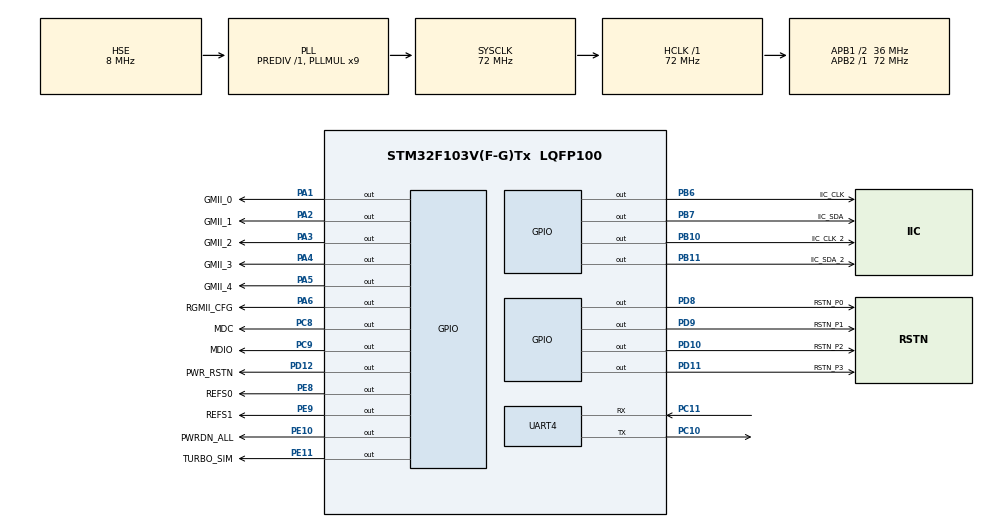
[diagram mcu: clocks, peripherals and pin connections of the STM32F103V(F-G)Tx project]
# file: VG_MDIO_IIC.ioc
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Dma.Request0=UART4_RX
Dma.UART4_RX.0.Direction=DMA_PERIPH_TO_MEMORY
Dma.UART4_RX.0.Instance=DMA2_Channel3
Dma.UART4_RX.0.MemDataAlignment=DMA_MDATAALIGN_BYTE
Dma.UART4_RX.0.MemInc=DMA_MINC_ENABLE
Dma.UART4_RX.0.Mode=DMA_NORMAL
Dma.UART4_RX.0.PeriphDataAlignment=DMA_PDATAALIGN_BYTE
Dma.UART4_RX.0.PeriphInc=DMA_PINC_DISABLE
Dma.UART4_RX.0.Priority=DMA_PRIORITY_LOW
Mcu.Family=STM32F1
Mcu.Name=STM32F103V(F-G)Tx
Mcu.Package=LQFP100
NVIC.DMA2_Channel3_IRQn=true\:0\:0\:false\:false\:true
NVIC.PriorityGroup=NVIC_PRIORITYGROUP_4
NVIC.UART4_IRQn=true\:0\:0\:false\:false\:true
OSC_IN.Mode=HSE-External-Oscillator
OSC_IN.Signal=RCC_OSC_IN
OSC_OUT.Mode=HSE-External-Oscillator
OSC_OUT.Signal=RCC_OSC_OUT
PA1.GPIO_Label=GMII_0
PA1.Signal=GPIO_Output
PA13.Mode=Serial_Wire
PA13.Signal=SYS_JTMS-SWDIO
PA14.Mode=Serial_Wire
PA14.Signal=SYS_JTCK-SWCLK
PA2.GPIO_Label=GMII_1
PA2.Signal=GPIO_Output
PA3.GPIO_Label=GMII_2
PA3.Signal=GPIO_Output
PA4.GPIO_Label=GMII_3
PA4.Signal=GPIO_Output
PA5.GPIO_Label=GMII_4
PA5.Signal=GPIO_Output
PA6.GPIO_Label=RGMII_CFG
PA6.PinState=GPIO_PIN_SET
PA6.Signal=GPIO_Output
PB10.GPIO_Label=IIC_CLK_2
PB10.Signal=GPIO_Output
PB11.GPIO_Label=IIC_SDA_2
PB11.Signal=GPIO_Output
PB6.GPIO_Label=IIC_CLK
PB6.Signal=GPIO_Output
PB7.GPIO_Label=IIC_SDA
PB7.Signal=GPIO_Output
PC10.Mode=Asynchronous
PC10.Signal=UART4_TX
PC11.Mode=Asynchronous
PC11.Signal=UART4_RX
PC8.GPIO_Label=MDC
PC8.Signal=GPIO_Output
PC9.GPIO_Label=MDIO
PC9.Signal=GPIO_Output
PD10.GPIO_Label=RSTN_P2
PD10.Signal=GPIO_Output
PD11.GPIO_Label=RSTN_P3
PD11.Signal=GPIO_Output
PD12.GPIO_Label=PWR_RSTN
PD12.PinState=GPIO_PIN_SET
PD12.Signal=GPIO_Output
PD8.GPIO_Label=RSTN_P0
PD8.Signal=GPIO_Output
PD9.GPIO_Label=RSTN_P1
PD9.Signal=GPIO_Output
PE10.GPIO_Label=PWRDN_ALL
PE10.Signal=GPIO_Output
PE11.GPIO_Label=TURBO_SIM
PE11.Signal=GPIO_Output
PE8.GPIO_Label=REFS0
PE8.Signal=GPIO_Output
PE9.GPIO_Label=REFS1
PE9.Signal=GPIO_Output
ProjectManager.HeapSize=0x200
ProjectManager.StackSize=0x400
ProjectManager.TargetToolchain=MDK-ARM V5
RCC.AHBFreq_Value=72000000
RCC.APB1CLKDivider=RCC_HCLK_DIV2
RCC.APB1Freq_Value=36000000
RCC.APB1TimFreq_Value=72000000
RCC.APB2Freq_Value=72000000
RCC.APB2TimFreq_Value=72000000
RCC.HCLKFreq_Value=72000000
RCC.HSIState=RCC_HSI_ON
RCC.PLLMUL=RCC_PLL_MUL9
RCC.PLLSourceVirtual=RCC_PLLSOURCE_HSE
RCC.SYSCLKFreq_VALUE=72000000
RCC.SYSCLKSource=RCC_SYSCLKSOURCE_PLLCLK
RCC.USBFreq_Value=72000000
board=VG_MDIO_IIC

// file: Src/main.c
/**
  ******************************************************************************
  * File Name          : main.c
  * Description        : Main program body
  ******************************************************************************
  *
  * COPYRIGHT(c) 2020 STMicroelectronics
  *
  * Redistribution and use in source and binary forms, with or without modification,
  * are permitted provided that the following conditions are met:
  *   1. Redistributions of source code must retain the above copyright notice,
  *      this list of conditions and the following disclaimer.
  *   2. Redistributions in binary form must reproduce the above copyright notice,
  *      this list of conditions and the following disclaimer in the documentation
  *      and/or other materials provided with the distribution.
  *   3. Neither the name of STMicroelectronics nor the names of its contributors
  *      may be used to endorse or promote products derived from this software
  *      without specific prior written permission.
  *
  * THIS SOFTWARE IS PROVIDED BY THE COPYRIGHT HOLDERS AND CONTRIBUTORS "AS IS"
  * AND ANY EXPRESS OR IMPLIED WARRANTIES, INCLUDING, BUT NOT LIMITED TO, THE
  * IMPLIED WARRANTIES OF MERCHANTABILITY AND FITNESS FOR A PARTICULAR PURPOSE ARE
  * DISCLAIMED. IN NO EVENT SHALL THE COPYRIGHT HOLDER OR CONTRIBUTORS BE LIABLE
  * FOR ANY DIRECT, INDIRECT, INCIDENTAL, SPECIAL, EXEMPLARY, OR CONSEQUENTIAL
  * DAMAGES (INCLUDING, BUT NOT LIMITED TO, PROCUREMENT OF SUBSTITUTE GOODS OR
  * SERVICES; LOSS OF USE, DATA, OR PROFITS; OR BUSINESS INTERRUPTION) HOWEVER
  * CAUSED AND ON ANY THEORY OF LIABILITY, WHETHER IN CONTRACT, STRICT LIABILITY,
  * OR TORT (INCLUDING NEGLIGENCE OR OTHERWISE) ARISING IN ANY WAY OUT OF THE USE
  * OF THIS SOFTWARE, EVEN IF ADVISED OF THE POSSIBILITY OF SUCH DAMAGE.
  *
  ******************************************************************************
  */
#include "stm32f1xx_hal.h"
#include "dma.h"
#include "usart.h"
#include "gpio.h"

/* USER CODE BEGIN Includes */
#include "mdio.h"
#include "mpu6050.h"
/* USER CODE END Includes */

/* USER CODE BEGIN PV */
/* Private variables ---------------------------------------------------------*/

/* USER CODE END PV */

void SystemClock_Config(void);
void Error_Handler(void);

/* USER CODE BEGIN PFP */
/* Private function prototypes -----------------------------------------------*/

/* USER CODE END PFP */

/* USER CODE BEGIN 0 */
void show(void)
{
	printf("\r\nIIC for RTL8367RB and PHY\r\n");
	printf("MDIO for PHY\r\n");

	help();
}
/* USER CODE END 0 */

int main(void)
{

  /* MCU Configuration----------------------------------------------------------*/

  /* Reset of all peripherals, Initializes the Flash interface and the Systick. */
  HAL_Init();

  /* Configure the system clock */
  SystemClock_Config();

  /* Initialize all configured peripherals */
  MX_GPIO_Init();
  MX_DMA_Init();
  MX_UART4_Init();

  /* USER CODE BEGIN 2 */
	show();
/* 开始串口空闲中断DMA接收 */
	uart4_start_receive_it();

	/* 初始化MPU6050 */
////		MPU6050_Init();
//
//	MPU6050_Read_Temperature();
//uint8_t buf[2];
//MPU6050_Read_Len(MPU6050_ADDR, 0xC0, 2, buf);

//	HAL_GPIO_WritePin(IIC_CLK_GPIO_Port, IIC_CLK_Pin, GPIO_PIN_SET);
//	HAL_GPIO_WritePin(IIC_SDA_GPIO_Port, IIC_SDA_Pin, GPIO_PIN_SET);
  /* USER CODE END 2 */

  /* Infinite loop */
  while (1)
  {

  /* USER CODE BEGIN 3 */
//		printf("hello world\r\n");
//		HAL_Delay(1000);

  }
  /* USER CODE END 3 */

}

/** System Clock Configuration
*/
void SystemClock_Config(void)
{

  RCC_OscInitTypeDef RCC_OscInitStruct;
  RCC_ClkInitTypeDef RCC_ClkInitStruct;

  RCC_OscInitStruct.OscillatorType = RCC_OSCILLATORTYPE_HSE;
  RCC_OscInitStruct.HSEState = RCC_HSE_ON;
  RCC_OscInitStruct.HSEPredivValue = RCC_HSE_PREDIV_DIV1;
  RCC_OscInitStruct.PLL.PLLState = RCC_PLL_ON;
  RCC_OscInitStruct.PLL.PLLSource = RCC_PLLSOURCE_HSE;
  RCC_OscInitStruct.PLL.PLLMUL = RCC_PLL_MUL9;
  if (HAL_RCC_OscConfig(&RCC_OscInitStruct) != HAL_OK)
  {
    Error_Handler();
  }

  RCC_ClkInitStruct.ClockType = RCC_CLOCKTYPE_HCLK|RCC_CLOCKTYPE_SYSCLK
                              |RCC_CLOCKTYPE_PCLK1|RCC_CLOCKTYPE_PCLK2;
  RCC_ClkInitStruct.SYSCLKSource = RCC_SYSCLKSOURCE_PLLCLK;
  RCC_ClkInitStruct.AHBCLKDivider = RCC_SYSCLK_DIV1;
  RCC_ClkInitStruct.APB1CLKDivider = RCC_HCLK_DIV2;
  RCC_ClkInitStruct.APB2CLKDivider = RCC_HCLK_DIV1;
  if (HAL_RCC_ClockConfig(&RCC_ClkInitStruct, FLASH_LATENCY_2) != HAL_OK)
  {
    Error_Handler();
  }

  HAL_SYSTICK_Config(HAL_RCC_GetHCLKFreq()/1000);

  HAL_SYSTICK_CLKSourceConfig(SYSTICK_CLKSOURCE_HCLK);

  /* SysTick_IRQn interrupt configuration */
  HAL_NVIC_SetPriority(SysTick_IRQn, 0, 0);
}

/* USER CODE BEGIN 4 */
int fputc(int ch, FILE *f)
{
  while(HAL_UART_GetState(&huart4) == HAL_UART_STATE_BUSY_TX){}
  HAL_UART_Transmit(&huart4, (uint8_t *)&ch, 1, 100);
  return ch;
}
/* USER CODE END 4 */

void Error_Handler(void)
{
  while(1)
  {
  }
}

/************************ (C) COPYRIGHT STMicroelectronics *****END OF FILE****/
